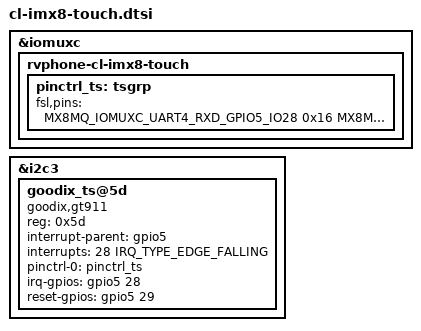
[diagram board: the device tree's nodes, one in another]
&iomuxc {
	rvphone-cl-imx8-touch {
		pinctrl_ts: tsgrp {
			fsl,pins = <
				MX8MQ_IOMUXC_UART4_RXD_GPIO5_IO28		0x16 /* TOUCH IRQ */
				MX8MQ_IOMUXC_UART4_TXD_GPIO5_IO29		0x16 /* TOUCH RST */
			>;
		};
	};
};

&i2c3 {
	status = "okay";
	goodix_ts@5d {
		compatible = "goodix,gt911";
		reg = <0x5d>;

		interrupt-parent = <&gpio5>;
		interrupts = <28 IRQ_TYPE_EDGE_FALLING>;

		pinctrl-names = "default";
		pinctrl-0 = <&pinctrl_ts>;

		irq-gpios = <&gpio5 28 GPIO_ACTIVE_HIGH>;
		reset-gpios = <&gpio5 29 GPIO_ACTIVE_HIGH>;
		status = "okay";
	};
};
